# M3U6 register map
File version: 2.0.2.11
Registers are 32-bit, read-write, reset 0x0 unless marked. A register's access mark holds for its fields unless they carry their own. Offsets are from the block's base; [hi:lo] are bit positions; {n}, {i} and the like mark numbered series.

## PJ — General Purpose Input_Output Port (PJ)
Base 0x40000240
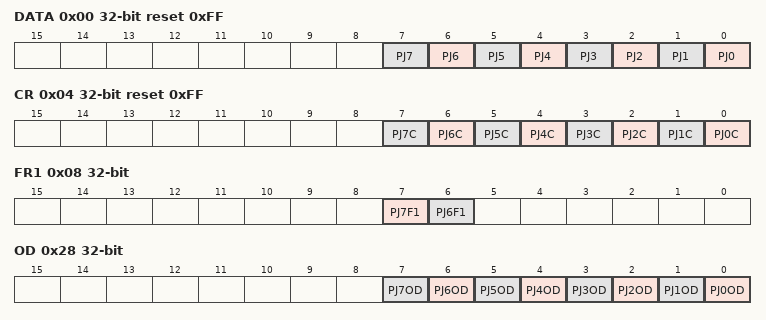
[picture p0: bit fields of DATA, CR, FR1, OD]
0x00 DATA reset 0xFF — PJ Data Register
  [n] PJ{n} (n=0..7)
0x04 CR reset 0xFF — PJ Control Register
  [n] PJ{n}C (n=0..7)
0x08 FR1 — PJ Function Register 1
  [7] PJ7F1, [6] PJ6F1
0x28 OD — PJ Open Drain Control Register
  [n] PJ{n}OD (n=0..7)
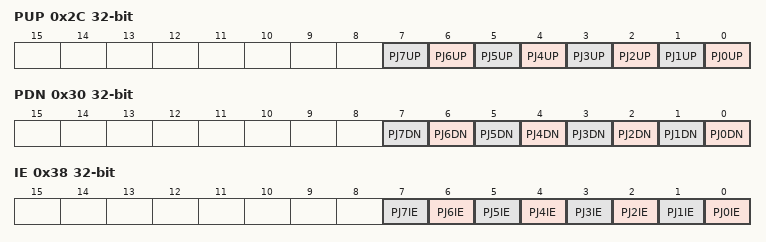
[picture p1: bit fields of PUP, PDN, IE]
0x2C PUP — PJ Pull-Up Control Register
  [n] PJ{n}UP (n=0..7)
0x30 PDN — PJ Pull-Down Control Register
  [n] PJ{n}DN (n=0..7)
0x38 IE — PJ Input Enable Control Register
  [n] PJ{n}IE (n=0..7)

## PL — General Purpose Input_Output Port (PL)
Base 0x400002C0
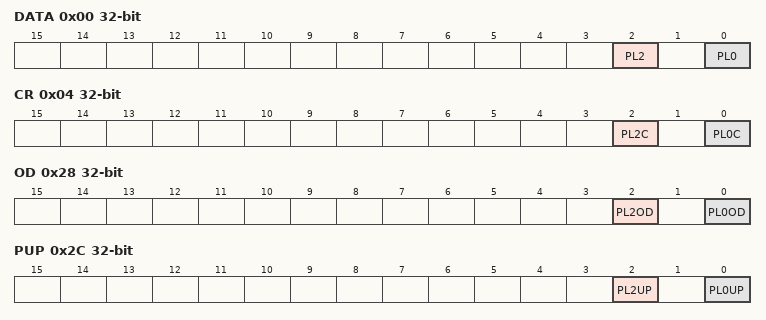
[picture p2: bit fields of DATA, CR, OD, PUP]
0x00 DATA — PL Data Register
  [2] PL2, [0] PL0
0x04 CR — PL Control Register
  [2] PL2C, [0] PL0C
0x08 FR1 — PL Function Register 1
  [2] PL2F1
0x28 OD — PL Open Drain Control Register
  [2] PL2OD, [0] PL0OD
0x2C PUP — PL Pull-Up Control Register
  [2] PL2UP, [0] PL0UP
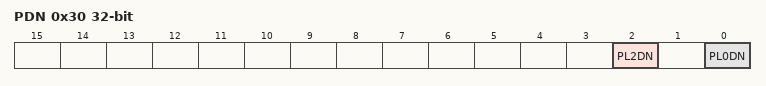
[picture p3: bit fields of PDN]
0x30 PDN — PL Pull-Down Control Register
  [2] PL2DN, [0] PL0DN
0x38 IE — PL Input Enable Control Register
  [2] PL2IE

## PM — General Purpose Input_Output Port (PM)
Base 0x40000300
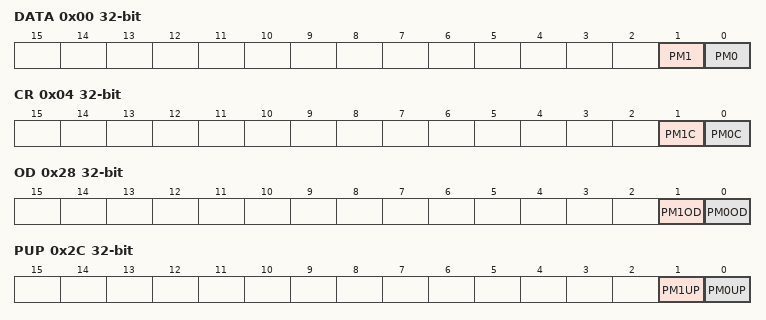
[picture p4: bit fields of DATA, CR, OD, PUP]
0x00 DATA — PM Data Register
  [1] PM1, [0] PM0
0x04 CR — PM Control Register
  [1] PM1C, [0] PM0C
0x28 OD — PM Open Drain Control Register
  [1] PM1OD, [0] PM0OD
0x2C PUP — PM Pull-Up Control Register
  [1] PM1UP, [0] PM0UP
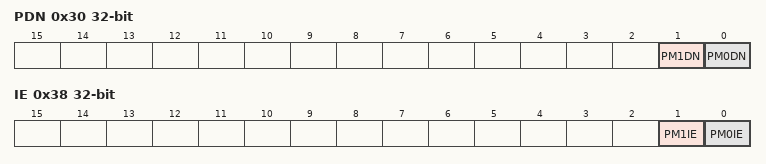
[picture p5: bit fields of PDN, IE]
0x30 PDN — PM Pull-Down Control Register
  [1] PM1DN, [0] PM0DN
0x38 IE — PM Input Enable Control Register
  [1] PM1IE, [0] PM0IE

## PN — General Purpose Input_Output Port (PN)
Base 0x40000340
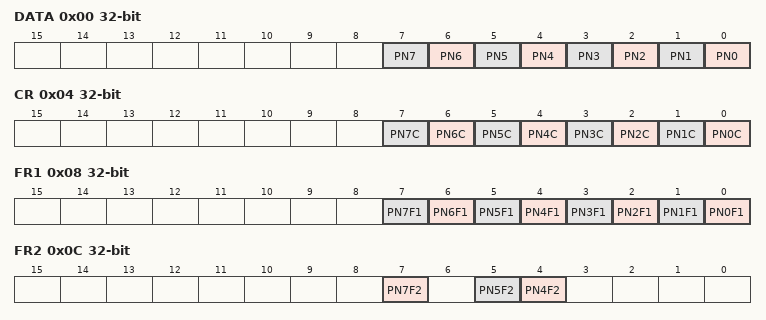
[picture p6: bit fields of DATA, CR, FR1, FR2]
0x00 DATA — PN Data Register
  [n] PN{n} (n=0..7)
0x04 CR — PN Control Register
  [n] PN{n}C (n=0..7)
0x08 FR1 — PN Function Register 1
  [n] PN{n}F1 (n=0..7)
0x0C FR2 — PN Function Register 2
  [7] PN7F2, [5] PN5F2, [4] PN4F2
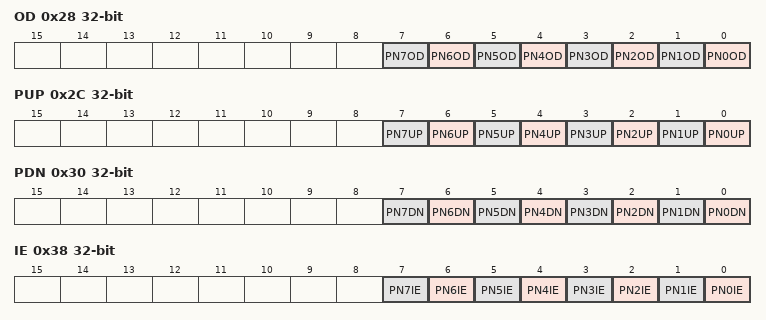
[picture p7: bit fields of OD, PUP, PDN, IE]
0x28 OD — PN Open Drain Control Register
  [n] PN{n}OD (n=0..7)
0x2C PUP — PN Pull-Up Control Register
  [n] PN{n}UP (n=0..7)
0x30 PDN — PN Pull-Down Control Register
  [n] PN{n}DN (n=0..7)
0x38 IE — PN Input Enable Control Register
  [n] PN{n}IE (n=0..7)

## PP — General Purpose Input_Output Port (PP)
Base 0x40000380
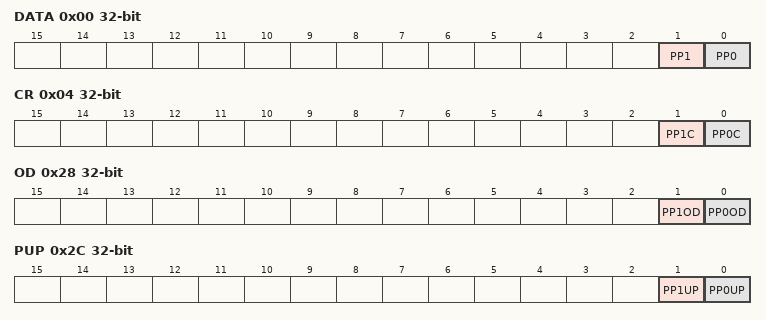
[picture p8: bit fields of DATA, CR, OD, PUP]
0x00 DATA — PP Data Register
  [1] PP1, [0] PP0
0x04 CR — PP Control Register
  [1] PP1C, [0] PP0C
0x28 OD — PP Open Drain Control Register
  [1] PP1OD, [0] PP0OD
0x2C PUP — PP Pull-Up Control Register
  [1] PP1UP, [0] PP0UP
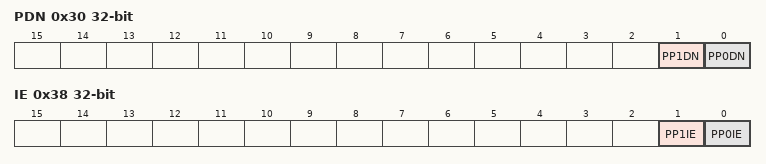
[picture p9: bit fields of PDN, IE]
0x30 PDN — PP Pull-Down Control Register
  [1] PP1DN, [0] PP0DN
0x38 IE — PP Input Enable Control Register
  [1] PP1IE, [0] PP0IE

## TB0 — 16-bit Timer_Event Counter (TB)
Base 0x40010000
Same registers: TB1 0x40010040, TB2 0x40010080, TB3 0x400100C0, TB4 0x40010100, TB5 0x40010140, TB6 0x40010180, TB7 0x400101C0
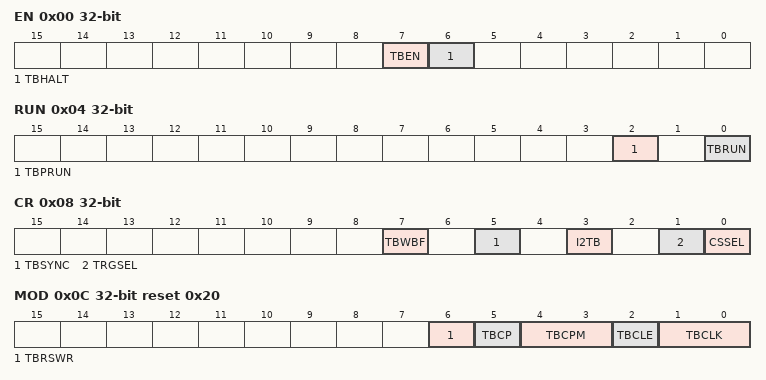
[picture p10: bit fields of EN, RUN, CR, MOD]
0x00 EN — TB Enable Register
  [7] TBEN, [6] TBHALT
0x04 RUN — TB RUN Register
  [2] TBPRUN, [0] TBRUN
0x08 CR — TB Control Register
  [7] TBWBF, [5] TBSYNC, [3] I2TB, [1] TRGSEL, [0] CSSEL
0x0C MOD reset 0x20 — TB Mode Register
  [6] TBRSWR, [5] TBCP wo, [4:3] TBCPM, [2] TBCLE, [1:0] TBCLK
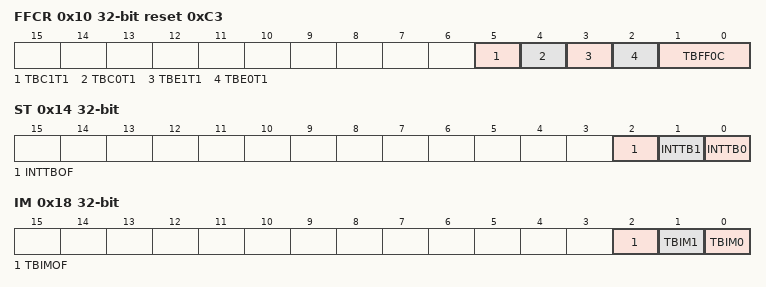
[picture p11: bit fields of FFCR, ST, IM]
0x10 FFCR reset 0xC3 — TB Flip-Flop Control Register
  [5] TBC1T1, [4] TBC0T1, [3] TBE1T1, [2] TBE0T1, [1:0] TBFF0C
0x14 ST ro — TB Status Register
  [2] INTTBOF, [1] INTTB1, [0] INTTB0
0x18 IM — TB Interrupt Mask Register
  [2] TBIMOF, [1] TBIM1, [0] TBIM0
0x1C UC ro — TB Read Capture Register
  [15:0] TBUC
0x20 RG0 — TB RG0 Timer Register
  [15:0] TBRG0
0x24 RG1 — TB RG1 Timer Register
  [15:0] TBRG1
0x28 CP0 ro (reset mask 0xFFFF0000) — TB CP0 Capture Register
  [15:0] TBCP0
0x2C CP1 ro (reset mask 0xFFFF0000) — TB CP1 Capture Register
  [15:0] TBCP1

## EN0 — Encoder Input (ENC)
Base 0x40010400
Same registers: EN1 0x40010500
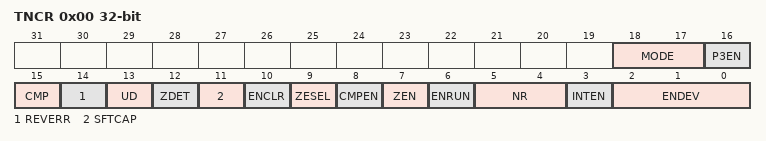
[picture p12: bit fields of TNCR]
0x00 TNCR — Encoder Input Control Register
  [18:17] MODE, [16] P3EN, [15] CMP ro, [14] REVERR ro, [13] UD ro, [12] ZDET ro, [11] SFTCAP wo, [10] ENCLR wo, [9] ZESEL, [8] CMPEN, [7] ZEN, [6] ENRUN, [5:4] NR, [3] INTEN, [2:0] ENDEV
0x04 RELOAD — Encoder Counter Reload Register
  [15:0] RELOAD
0x08 INT — Encoder Compare Register
  [23:0] INT
0x0C CNT ro — Encoder Counter Register
  [23:0] CNT
